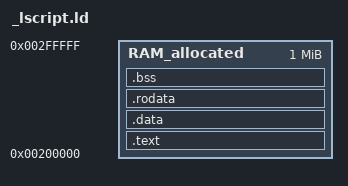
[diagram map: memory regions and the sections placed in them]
# Autogenerated lscript for partition term
MEMORY
{
   RAM_allocated : ORIGIN = 0x200000, LENGTH = 0x00100000
}

ENTRY(main)

SECTIONS
{
    .text : {
        *(.text)
    } > RAM_allocated
    .data : {
        *(.text)
    } > RAM_allocated
    .rodata : {
        *(.text)
    } > RAM_allocated
    .bss : {
        *(.text)
    } > RAM_allocated
}
